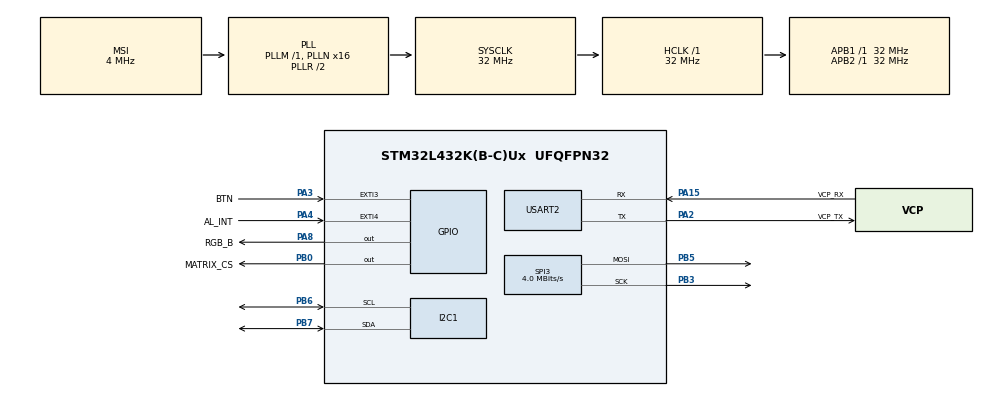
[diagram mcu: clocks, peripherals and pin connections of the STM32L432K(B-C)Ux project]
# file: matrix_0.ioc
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I2C1.Timing=0x00B07CB4
Mcu.Family=STM32L4
Mcu.Name=STM32L432K(B-C)Ux
Mcu.Package=UFQFPN32
NVIC.EXTI3_IRQn=true\:0\:0\:false\:false\:true\:true\:true\:true
NVIC.EXTI4_IRQn=true\:0\:0\:false\:false\:true\:true\:true\:true
NVIC.PriorityGroup=NVIC_PRIORITYGROUP_4
NVIC.TIM6_DAC_IRQn=true\:0\:0\:false\:false\:true\:true\:true\:true
PA0.GPIO_Label=MCO [High speed clock in]
PA0.Signal=RCC_CK_IN
PA13\ (JTMS-SWDIO).GPIO_Label=SWDIO
PA13\ (JTMS-SWDIO).Signal=SYS_JTMS-SWDIO
PA14\ (JTCK-SWCLK).GPIO_Label=SWCLK
PA14\ (JTCK-SWCLK).Signal=SYS_JTCK-SWCLK
PA15\ (JTDI).GPIO_Label=VCP_RX
PA15\ (JTDI).Mode=Asynchronous
PA15\ (JTDI).Signal=USART2_RX
PA2.GPIO_Label=VCP_TX
PA2.Mode=Asynchronous
PA2.Signal=USART2_TX
PA3.GPIO_Label=BTN
PA3.GPIO_ModeDefaultEXTI=GPIO_MODE_IT_RISING_FALLING
PA3.GPIO_PuPd=GPIO_PULLUP
PA3.Signal=GPXTI3
PA4.GPIO_Label=AL_INT
PA4.GPIO_ModeDefaultEXTI=GPIO_MODE_IT_RISING_FALLING
PA4.GPIO_PuPd=GPIO_PULLUP
PA4.Signal=GPXTI4
PA8.GPIO_Label=RGB_B
PA8.PinState=GPIO_PIN_SET
PA8.Signal=GPIO_Output
PB0.GPIO_Label=MATRIX_CS
PB0.PinState=GPIO_PIN_SET
PB0.Signal=GPIO_Output
PB3\ (JTDO-TRACESWO).Mode=TX_Only_Simplex_Unidirect_Master
PB3\ (JTDO-TRACESWO).Signal=SPI3_SCK
PB5.Mode=TX_Only_Simplex_Unidirect_Master
PB5.Signal=SPI3_MOSI
PB6.Mode=I2C
PB6.Signal=I2C1_SCL
PB7.Mode=I2C
PB7.Signal=I2C1_SDA
PC14-OSC32_IN\ (PC14).Signal=RCC_OSC32_IN
PC15-OSC32_OUT\ (PC15).Signal=RCC_OSC32_OUT
ProjectManager.HeapSize=0x200
ProjectManager.StackSize=0x400
ProjectManager.TargetToolchain=STM32CubeIDE
RCC.AHBFreq_Value=32000000
RCC.APB1Freq_Value=32000000
RCC.APB1TimFreq_Value=32000000
RCC.APB2Freq_Value=32000000
RCC.APB2TimFreq_Value=32000000
RCC.CortexFreq_Value=32000000
RCC.HCLKFreq_Value=32000000
RCC.HSE_VALUE=8000000
RCC.HSI16_VALUE=16000000
RCC.HSI48_VALUE=48000000
RCC.HSI_VALUE=16000000
RCC.LSE_VALUE=32768
RCC.MSI_VALUE=4000000
RCC.PLLMUL=RCC_PLLMUL_4
RCC.PLLN=16
RCC.SYSCLKFreq_VALUE=32000000
RCC.SYSCLKSource=RCC_SYSCLKSOURCE_PLLCLK
RCC.VCOOutputFreq_Value=64000000
SPI3.BaudRatePrescaler=SPI_BAUDRATEPRESCALER_8
SPI3.CalculateBaudRate=4.0 MBits/s
SPI3.DataSize=SPI_DATASIZE_8BIT
SPI3.Direction=SPI_DIRECTION_2LINES
SPI3.Mode=SPI_MODE_MASTER
SPI3.VirtualType=VM_MASTER
TIM6.Period=500 - 1
TIM6.Prescaler=3200-1
USART2.VirtualMode-Asynchronous=VM_ASYNC
VP_TIM6_VS_ClockSourceINT.Mode=Enable_Timer
board=NUCLEO-L432KC

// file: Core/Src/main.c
/* USER CODE BEGIN Header */
/**
  ******************************************************************************
  * @file           : main.c
  * @brief          : Main program body
  ******************************************************************************
  * @attention
  *
  * Copyright (c) 2026 STMicroelectronics.
  * All rights reserved.
  *
  * This software is licensed under terms that can be found in the LICENSE file
  * in the root directory of this software component.
  * If no LICENSE file comes with this software, it is provided AS-IS.
  *
  ******************************************************************************
  */
/* USER CODE END Header */
#include "main.h"

/* USER CODE BEGIN Includes */
#include "max7219.h"
#include "thermo3.h"
#include <stdio.h>
#include <string.h>
/* USER CODE END Includes */

I2C_HandleTypeDef hi2c1;

SPI_HandleTypeDef hspi3;

TIM_HandleTypeDef htim6;

UART_HandleTypeDef huart2;

void SystemClock_Config(void);
static void MX_GPIO_Init(void);
static void MX_SPI3_Init(void);
static void MX_USART2_UART_Init(void);
static void MX_I2C1_Init(void);
static void MX_TIM6_Init(void);

/* USER CODE BEGIN 0 */
// Eigene Datentypen für bessere Lesbarkeit
typedef enum { UNIT_C, UNIT_F, UNIT_K } TempUnit_t;

// Unsere Zustandsvariablen
TempUnit_t current_unit = UNIT_C;
uint8_t current_rotation = 0; // 0 = 0°, 1 = 90°, 2 = 180°, 3 = 270°

// Variablen für die Zeitmessung und Kommunikation mit der main-Schleife
volatile uint32_t press_start_time = 0;
//volatile uint8_t state_changed_flag = 0; // 1 = Es gab eine Änderung, UART muss senden
// NEU für den Timer:
volatile int scroll_offset = 0;
// ÄNDERUNG: Flag auf 0 setzen, damit "SENSOR OK" erstmal scrollen darf!
volatile uint8_t scroll_finished_flag = 0;
/* USER CODE END 0 */

int main(void)
{

  /* MCU Configuration--------------------------------------------------------*/

  /* Reset of all peripherals, Initializes the Flash interface and the Systick. */
  HAL_Init();

  /* Configure the system clock */
  SystemClock_Config();

  /* Initialize all configured peripherals */
  MX_GPIO_Init();
  MX_SPI3_Init();
  MX_USART2_UART_Init();
  MX_I2C1_Init();
  MX_TIM6_Init();
  /* USER CODE BEGIN 2 */
      MAX7219_Init();

      // Wichtig: Dem Sensor nach dem Einschalten kurz Zeit zum Hochfahren geben!
      HAL_Delay(50);

      if (thermo3_init(&hi2c1) == THERMO3_OK)
      {
          thermo3_set_alert_pin(AL_INT_GPIO_Port, AL_INT_Pin);
          thermo3_set_limits(2500, 2800); // 25°C bis 28°C

          // Initiale LED setzen (Nur noch RGB_B: AN = Normal, AUS = Alarm)
		  if (thermo3_alert_active() == 1) // 1 = ALARM (zu heiß!)
		  {
			  HAL_GPIO_WritePin(RGB_G_GPIO_Port, RGB_G_Pin, GPIO_PIN_SET);   // Grün AUS (Alarm, heiß)
		  }
		  else // 0 = NORMAL
		  {
			  HAL_GPIO_WritePin(RGB_G_GPIO_Port, RGB_G_Pin, GPIO_PIN_RESET); // Grün an (Normal)
		  }

          MAX7219_LoadString("SENSOR OK ");
      }
      else
      {
          MAX7219_LoadString("I2C ERR ");
      }

      // Timer für das Display starten
      HAL_TIM_Base_Start_IT(&htim6);
  /* USER CODE END 2 */

  /* Infinite loop */
  /* USER CODE BEGIN WHILE */

  char uart_buf[64];
  char display_buf[32];
  int16_t raw_temp = 0;
  int32_t centi_c = 0;
  int32_t display_val = 0;

  while (1)
  {
      // Nur ausführen, wenn der Text einmal komplett durchgelaufen ist!
      if (scroll_finished_flag == 1)
      {
          scroll_finished_flag = 0; // Flag sofort wieder löschen

          // --- 1. SENSOR AUSLESEN ---
          if (thermo3_read_raw(&raw_temp) == THERMO3_OK)
          {
              centi_c = thermo3_raw_to_centi_c(raw_temp);
              char unit_char = 'C';
              display_val = centi_c;

              if (current_unit == UNIT_F) {
                  display_val = thermo3_centi_c_to_centi_f(centi_c);
                  unit_char = 'F';
              } else if (current_unit == UNIT_K) {
                  display_val = centi_c + 27315;
                  unit_char = 'K';
              }

              int32_t abs_val = (display_val < 0) ? -display_val : display_val;
              int part_int = abs_val / 100;
              int part_frac = abs_val % 100;

              if (display_val < 0) {
                  sprintf(display_buf, "-%d.%02d %c", part_int, part_frac, unit_char);
              } else {
                  sprintf(display_buf, "%d.%02d %c", part_int, part_frac, unit_char);
              }

              sprintf(uart_buf, "Live-Temp: %s\r\n", display_buf);
              HAL_UART_Transmit(&huart2, (uint8_t*)uart_buf, strlen(uart_buf), 100);

              // --- 2. NEUEN TEXT IN DEN PUFFER LADEN ---
              // Da wir das hier nur machen, wenn das Display gerade nicht mitten
              // im Text steht, gibt es keine Bildfehler (Tearing)!
              MAX7219_LoadString(display_buf);
          }
          else
          {
              MAX7219_LoadString("ERR ");
          }
      }

      // Hier unten KÖNNTE der Mikrocontroller jetzt für 50ms in einen
      // Stromsparmodus (Sleep) gehen. Für uns reicht ein "leeres" Drehen.
    /* USER CODE END WHILE */

  }
}

void SystemClock_Config(void)
{
  RCC_OscInitTypeDef RCC_OscInitStruct = {0};
  RCC_ClkInitTypeDef RCC_ClkInitStruct = {0};

  /** Configure the main internal regulator output voltage
  */
  if (HAL_PWREx_ControlVoltageScaling(PWR_REGULATOR_VOLTAGE_SCALE1) != HAL_OK)
  {
    Error_Handler();
  }

  /** Initializes the RCC Oscillators according to the specified parameters
  * in the RCC_OscInitTypeDef structure.
  */
  RCC_OscInitStruct.OscillatorType = RCC_OSCILLATORTYPE_MSI;
  RCC_OscInitStruct.MSIState = RCC_MSI_ON;
  RCC_OscInitStruct.MSICalibrationValue = 0;
  RCC_OscInitStruct.MSIClockRange = RCC_MSIRANGE_6;
  RCC_OscInitStruct.PLL.PLLState = RCC_PLL_ON;
  RCC_OscInitStruct.PLL.PLLSource = RCC_PLLSOURCE_MSI;
  RCC_OscInitStruct.PLL.PLLM = 1;
  RCC_OscInitStruct.PLL.PLLN = 16;
  RCC_OscInitStruct.PLL.PLLP = RCC_PLLP_DIV7;
  RCC_OscInitStruct.PLL.PLLQ = RCC_PLLQ_DIV2;
  RCC_OscInitStruct.PLL.PLLR = RCC_PLLR_DIV2;
  if (HAL_RCC_OscConfig(&RCC_OscInitStruct) != HAL_OK)
  {
    Error_Handler();
  }

  /** Initializes the CPU, AHB and APB buses clocks
  */
  RCC_ClkInitStruct.ClockType = RCC_CLOCKTYPE_HCLK|RCC_CLOCKTYPE_SYSCLK
                              |RCC_CLOCKTYPE_PCLK1|RCC_CLOCKTYPE_PCLK2;
  RCC_ClkInitStruct.SYSCLKSource = RCC_SYSCLKSOURCE_PLLCLK;
  RCC_ClkInitStruct.AHBCLKDivider = RCC_SYSCLK_DIV1;
  RCC_ClkInitStruct.APB1CLKDivider = RCC_HCLK_DIV1;
  RCC_ClkInitStruct.APB2CLKDivider = RCC_HCLK_DIV1;

  if (HAL_RCC_ClockConfig(&RCC_ClkInitStruct, FLASH_LATENCY_1) != HAL_OK)
  {
    Error_Handler();
  }
}

static void MX_I2C1_Init(void)
{

  hi2c1.Instance = I2C1;
  hi2c1.Init.Timing = 0x00B07CB4;
  hi2c1.Init.OwnAddress1 = 0;
  hi2c1.Init.AddressingMode = I2C_ADDRESSINGMODE_7BIT;
  hi2c1.Init.DualAddressMode = I2C_DUALADDRESS_DISABLE;
  hi2c1.Init.OwnAddress2 = 0;
  hi2c1.Init.OwnAddress2Masks = I2C_OA2_NOMASK;
  hi2c1.Init.GeneralCallMode = I2C_GENERALCALL_DISABLE;
  hi2c1.Init.NoStretchMode = I2C_NOSTRETCH_DISABLE;
  if (HAL_I2C_Init(&hi2c1) != HAL_OK)
  {
    Error_Handler();
  }

  /** Configure Analogue filter
  */
  if (HAL_I2CEx_ConfigAnalogFilter(&hi2c1, I2C_ANALOGFILTER_ENABLE) != HAL_OK)
  {
    Error_Handler();
  }

  /** Configure Digital filter
  */
  if (HAL_I2CEx_ConfigDigitalFilter(&hi2c1, 0) != HAL_OK)
  {
    Error_Handler();
  }

}

static void MX_SPI3_Init(void)
{

  /* SPI3 parameter configuration*/
  hspi3.Instance = SPI3;
  hspi3.Init.Mode = SPI_MODE_MASTER;
  hspi3.Init.Direction = SPI_DIRECTION_2LINES;
  hspi3.Init.DataSize = SPI_DATASIZE_8BIT;
  hspi3.Init.CLKPolarity = SPI_POLARITY_LOW;
  hspi3.Init.CLKPhase = SPI_PHASE_1EDGE;
  hspi3.Init.NSS = SPI_NSS_SOFT;
  hspi3.Init.BaudRatePrescaler = SPI_BAUDRATEPRESCALER_8;
  hspi3.Init.FirstBit = SPI_FIRSTBIT_MSB;
  hspi3.Init.TIMode = SPI_TIMODE_DISABLE;
  hspi3.Init.CRCCalculation = SPI_CRCCALCULATION_DISABLE;
  hspi3.Init.CRCPolynomial = 7;
  hspi3.Init.CRCLength = SPI_CRC_LENGTH_DATASIZE;
  hspi3.Init.NSSPMode = SPI_NSS_PULSE_ENABLE;
  if (HAL_SPI_Init(&hspi3) != HAL_OK)
  {
    Error_Handler();
  }

}

static void MX_TIM6_Init(void)
{

  TIM_MasterConfigTypeDef sMasterConfig = {0};

  htim6.Instance = TIM6;
  htim6.Init.Prescaler = 3200-1;
  htim6.Init.CounterMode = TIM_COUNTERMODE_UP;
  htim6.Init.Period = 500 - 1;
  htim6.Init.AutoReloadPreload = TIM_AUTORELOAD_PRELOAD_DISABLE;
  if (HAL_TIM_Base_Init(&htim6) != HAL_OK)
  {
    Error_Handler();
  }
  sMasterConfig.MasterOutputTrigger = TIM_TRGO_RESET;
  sMasterConfig.MasterSlaveMode = TIM_MASTERSLAVEMODE_DISABLE;
  if (HAL_TIMEx_MasterConfigSynchronization(&htim6, &sMasterConfig) != HAL_OK)
  {
    Error_Handler();
  }

}

static void MX_USART2_UART_Init(void)
{

  huart2.Instance = USART2;
  huart2.Init.BaudRate = 115200;
  huart2.Init.WordLength = UART_WORDLENGTH_8B;
  huart2.Init.StopBits = UART_STOPBITS_1;
  huart2.Init.Parity = UART_PARITY_NONE;
  huart2.Init.Mode = UART_MODE_TX_RX;
  huart2.Init.HwFlowCtl = UART_HWCONTROL_NONE;
  huart2.Init.OverSampling = UART_OVERSAMPLING_16;
  huart2.Init.OneBitSampling = UART_ONE_BIT_SAMPLE_DISABLE;
  huart2.AdvancedInit.AdvFeatureInit = UART_ADVFEATURE_NO_INIT;
  if (HAL_UART_Init(&huart2) != HAL_OK)
  {
    Error_Handler();
  }

}

static void MX_GPIO_Init(void)
{
  GPIO_InitTypeDef GPIO_InitStruct = {0};

  /* GPIO Ports Clock Enable */
  __HAL_RCC_GPIOC_CLK_ENABLE();
  __HAL_RCC_GPIOA_CLK_ENABLE();
  __HAL_RCC_GPIOB_CLK_ENABLE();

  /*Configure GPIO pin Output Level */
  HAL_GPIO_WritePin(MATRIX_CS_GPIO_Port, MATRIX_CS_Pin, GPIO_PIN_SET);

  /*Configure GPIO pin Output Level */
  HAL_GPIO_WritePin(RGB_G_GPIO_Port, RGB_G_Pin, GPIO_PIN_SET);

  /*Configure GPIO pins : BTN_Pin AL_INT_Pin */
  GPIO_InitStruct.Pin = BTN_Pin|AL_INT_Pin;
  GPIO_InitStruct.Mode = GPIO_MODE_IT_RISING_FALLING;
  GPIO_InitStruct.Pull = GPIO_PULLUP;
  HAL_GPIO_Init(GPIOA, &GPIO_InitStruct);

  /*Configure GPIO pin : MATRIX_CS_Pin */
  GPIO_InitStruct.Pin = MATRIX_CS_Pin;
  GPIO_InitStruct.Mode = GPIO_MODE_OUTPUT_PP;
  GPIO_InitStruct.Pull = GPIO_NOPULL;
  GPIO_InitStruct.Speed = GPIO_SPEED_FREQ_LOW;
  HAL_GPIO_Init(MATRIX_CS_GPIO_Port, &GPIO_InitStruct);

  /*Configure GPIO pin : RGB_B_Pin */
  GPIO_InitStruct.Pin = RGB_G_Pin;
  GPIO_InitStruct.Mode = GPIO_MODE_OUTPUT_PP;
  GPIO_InitStruct.Pull = GPIO_NOPULL;
  GPIO_InitStruct.Speed = GPIO_SPEED_FREQ_LOW;
  HAL_GPIO_Init(RGB_G_GPIO_Port, &GPIO_InitStruct);

  /* EXTI interrupt init*/
  HAL_NVIC_SetPriority(EXTI3_IRQn, 0, 0);
  HAL_NVIC_EnableIRQ(EXTI3_IRQn);

  HAL_NVIC_SetPriority(EXTI4_IRQn, 0, 0);
  HAL_NVIC_EnableIRQ(EXTI4_IRQn);

}

/* USER CODE BEGIN 4 */
void HAL_GPIO_EXTI_Callback(uint16_t GPIO_Pin)
{
    // --- 1. Button (Kurz/Lang Klick) ---
    if (GPIO_Pin == BTN_Pin)
    {
        if (HAL_GPIO_ReadPin(BTN_GPIO_Port, BTN_Pin) == GPIO_PIN_RESET)
        {
            press_start_time = HAL_GetTick();
        }
        else
        {
            uint32_t press_duration = HAL_GetTick() - press_start_time;

            if (press_duration >= 1000)
            {
                current_rotation = (current_rotation + 1) % 4;
            }
            else if (press_duration >= 50)
            {
                if (current_unit == UNIT_C) current_unit = UNIT_F;
                else if (current_unit == UNIT_F) current_unit = UNIT_K;
                else current_unit = UNIT_C;
            }
            else
            {
                return; // Prellen abfangen
            }

            char unit_char = 'C';
            if (current_unit == UNIT_F) unit_char = 'F';
            if (current_unit == UNIT_K) unit_char = 'K';

            char uart_buf[100];
            sprintf(uart_buf, "Update! Einheit: %c | Drehung: %d Grad\r\n", unit_char, current_rotation * 90);
            HAL_UART_Transmit(&huart2, (uint8_t*)uart_buf, strlen(uart_buf), 100);
        }
    }

    // --- 2. Hardware-Alarm vom TMP102 (Nur RGB_B Steuerung) ---
	if (GPIO_Pin == AL_INT_Pin)
	{
		// Comparator Mode: Pin ist Active LOW (0 = Heiß, 1 = Kalt)
		if (HAL_GPIO_ReadPin(AL_INT_GPIO_Port, AL_INT_Pin) == GPIO_PIN_RESET)
		{
			// T_HIGH ÜBERSCHRITTEN -> ALARM! (Blau AUS)
			HAL_GPIO_WritePin(RGB_G_GPIO_Port, RGB_G_Pin, GPIO_PIN_SET);
		}
		else
		{
			// WIEDER UNTER T_LOW -> NORMAL! (Blau AN)
			HAL_GPIO_WritePin(RGB_G_GPIO_Port, RGB_G_Pin, GPIO_PIN_RESET);
		}
    }
}

void HAL_TIM_PeriodElapsedCallback(TIM_HandleTypeDef *htim)
{
    // Prüfen, ob es wirklich TIM6 war
    if (htim->Instance == TIM6)
    {
        // Das Bild eine Spalte weiter zeichnen
        MAX7219_ShowWindow(scroll_offset, current_rotation);

        // Offset erhöhen
        scroll_offset++;

        // Wenn der Text einmal komplett durchgelaufen ist:
        if (scroll_offset >= scroll_length)
        {
            scroll_offset = 0;             // Zurück auf Start
            scroll_finished_flag = 1;      // Der Main-Schleife Bescheid geben!
        }
    }
}
/* USER CODE END 4 */

void Error_Handler(void)
{
  __disable_irq();
  while (1)
  {
  }
}
